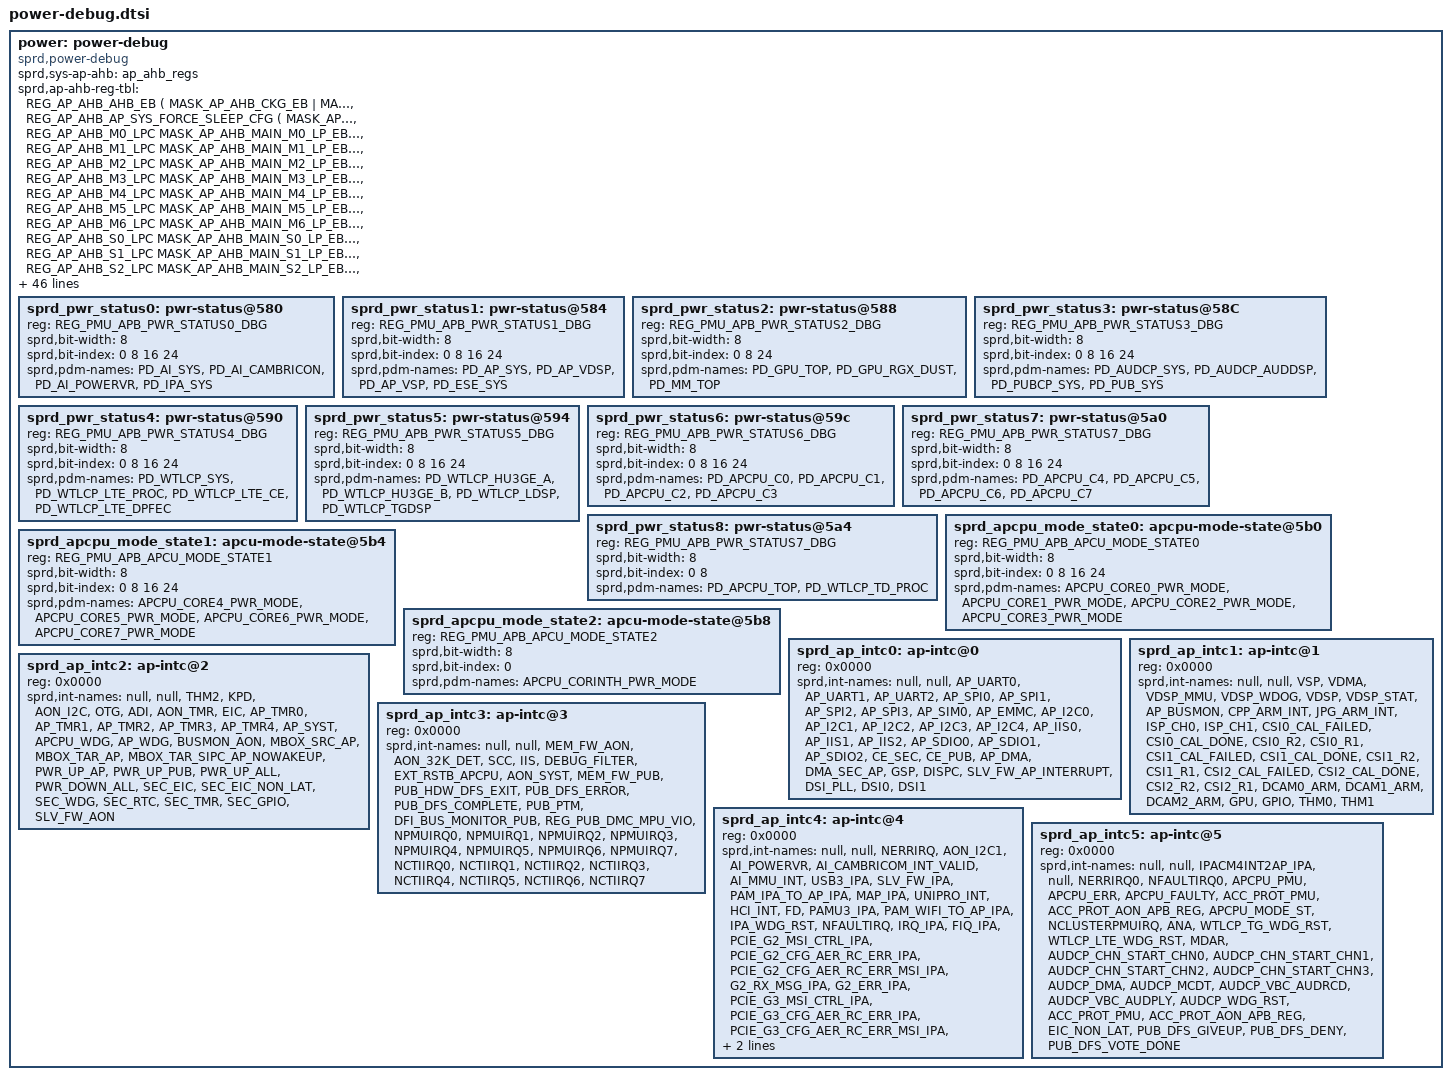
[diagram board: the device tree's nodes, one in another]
/*
 * Spreadtrum Roc1 SoC DTS file
 *
 * Copyright (C) 2018, Spreadtrum Communications Inc.
 *
 * This file is licensed under a dual GPLv2 or X11 license.
 */

	power: power-debug {
		compatible = "sprd,power-debug";
		#address-cells = <1>;
		#size-cells = <0>;

		sprd,sys-ap-ahb = <&ap_ahb_regs>;

		/* <reg-addr mask expect-value> */
		sprd,ap-ahb-reg-tbl =
			<REG_AP_AHB_AHB_EB
			( MASK_AP_AHB_CKG_EB
			| MASK_AP_AHB_DMA_EB
			| MASK_AP_AHB_DMA_ENABLE
			| MASK_AP_AHB_VSP_EB
			| MASK_AP_AHB_DISPC_EB
			| MASK_AP_AHB_DSI_EB )
			MASK_AP_AHB_CKG_EB>,
			<REG_AP_AHB_AP_SYS_FORCE_SLEEP_CFG
			( MASK_AP_AHB_AXI_LP_CTRL_DISABLE
			| MASK_AP_AHB_PERI_FORCE_OFF )
			( MASK_AP_AHB_AXI_LP_CTRL_DISABLE
			| MASK_AP_AHB_PERI_FORCE_OFF)>,
			<REG_AP_AHB_M0_LPC MASK_AP_AHB_MAIN_M0_LP_EB MASK_AP_AHB_MAIN_M0_LP_EB>,
			<REG_AP_AHB_M1_LPC MASK_AP_AHB_MAIN_M1_LP_EB MASK_AP_AHB_MAIN_M1_LP_EB>,
			<REG_AP_AHB_M2_LPC MASK_AP_AHB_MAIN_M2_LP_EB MASK_AP_AHB_MAIN_M2_LP_EB>,
			<REG_AP_AHB_M3_LPC MASK_AP_AHB_MAIN_M3_LP_EB MASK_AP_AHB_MAIN_M3_LP_EB>,
			<REG_AP_AHB_M4_LPC MASK_AP_AHB_MAIN_M4_LP_EB MASK_AP_AHB_MAIN_M4_LP_EB>,
			<REG_AP_AHB_M5_LPC MASK_AP_AHB_MAIN_M5_LP_EB MASK_AP_AHB_MAIN_M5_LP_EB>,
			<REG_AP_AHB_M6_LPC MASK_AP_AHB_MAIN_M6_LP_EB MASK_AP_AHB_MAIN_M6_LP_EB>,
			<REG_AP_AHB_S0_LPC MASK_AP_AHB_MAIN_S0_LP_EB MASK_AP_AHB_MAIN_S0_LP_EB>,
			<REG_AP_AHB_S1_LPC MASK_AP_AHB_MAIN_S1_LP_EB MASK_AP_AHB_MAIN_S1_LP_EB>,
			<REG_AP_AHB_S2_LPC MASK_AP_AHB_MAIN_S2_LP_EB MASK_AP_AHB_MAIN_S2_LP_EB>,
			<REG_AP_AHB_S3_LPC MASK_AP_AHB_MAIN_S3_LP_EB MASK_AP_AHB_MAIN_S3_LP_EB>,
			<REG_AP_AHB_S4_LPC MASK_AP_AHB_MAIN_S4_LP_EB MASK_AP_AHB_MAIN_S4_LP_EB>,
			<REG_AP_AHB_S5_LPC MASK_AP_AHB_MAIN_S5_LP_EB MASK_AP_AHB_MAIN_S5_LP_EB>,
			<REG_AP_AHB_S6_LPC MASK_AP_AHB_MAIN_S6_LP_EB MASK_AP_AHB_MAIN_S6_LP_EB>,
			<REG_AP_AHB_MERGE_M1_LPC MASK_AP_AHB_MERGE_M1_LP_EB MASK_AP_AHB_MERGE_M1_LP_EB>,
			<REG_AP_AHB_MERGE_S0_LPC MASK_AP_AHB_MERGE_S0_LP_EB MASK_AP_AHB_MERGE_S0_LP_EB>,
			<REG_AP_AHB_DISP_ASYNC_BRG MASK_AP_AHB_DISP_ASYNC_BRG_LP_EB MASK_AP_AHB_DISP_ASYNC_BRG_LP_EB>,
			<REG_AP_AHB_AP_ASYNC_BRG MASK_AP_AHB_AP_ASYNC_BRG_LP_EB MASK_AP_AHB_AP_ASYNC_BRG_LP_EB>;

		sprd,sys-ap-apb = <&ap_apb_regs>;

		sprd,ap-apb-reg-tbl =
			<REG_AP_APB_APB_EB
			( MASK_AP_APB_CE_PUB_EB
			| MASK_AP_APB_CE_SEC_EB
			| MASK_AP_APB_EMMC_EB
			| MASK_AP_APB_SDIO2_EB
			| MASK_AP_APB_SDIO1_EB
			| MASK_AP_APB_SDIO0_EB
			| MASK_AP_APB_UART2_EB
			| MASK_AP_APB_UART1_EB
			| MASK_AP_APB_UART0_EB
			| MASK_AP_APB_I2C4_EB
			| MASK_AP_APB_I2C3_EB
			| MASK_AP_APB_I2C2_EB
			| MASK_AP_APB_I2C1_EB
			| MASK_AP_APB_I2C0_EB
			| MASK_AP_APB_SPI3_EB
			| MASK_AP_APB_SPI2_EB
			| MASK_AP_APB_SPI1_EB
			| MASK_AP_APB_SPI0_EB
			| MASK_AP_APB_IIS2_EB
			| MASK_AP_APB_IIS1_EB
			| MASK_AP_APB_IIS0_EB
			| MASK_AP_APB_SIM0_EB )
			0x00000000>,
			<REG_AP_APB_EB_SEC
			( MASK_AP_APB_SPI3_EB_SEC
			| MASK_AP_APB_SPI2_EB_SEC
			| MASK_AP_APB_SPI1_EB_SEC
			| MASK_AP_APB_SPI0_EB_SEC
			| MASK_AP_APB_I2C4_EB_SEC
			| MASK_AP_APB_I2C3_EB_SEC
			| MASK_AP_APB_I2C2_EB_SEC
			| MASK_AP_APB_I2C1_EB_SEC
			| MASK_AP_APB_I2C0_EB_SEC )
			0x00000000>,
			<REG_AP_APB_APB_EB1
			( MASK_AP_APB_UFS_UTP_EB
			| MASK_AP_APB_UFS_HCI_EB
			| MASK_AP_APB_UFS_UNIPRO_EB
			| MASK_AP_APB_UFS_EB )
			0x00000000>;

		sprd,sys-pmu-apb = <&pmu_apb_regs>;

		sprd,pmu-apb-reg-tbl =
			<REG_PMU_APB_PUB_SYS_AUTO_LIGHT_SLEEP_ENABLE MASK_PMU_APB_PUB_SYS_AUTO_LIGHT_SLEEP_ENABLE 0x00000000>,
			<REG_PMU_APB_SLEEP_CTRL
			( MASK_PMU_APB_IPA_DEEP_SLEEP
			| MASK_PMU_APB_SP_SYS_DEEP_SLEEP
			| MASK_PMU_APB_AUDCP_DEEP_SLEEP
			| MASK_PMU_APB_PUB_SYS_DEEP_SLEEP
			| MASK_PMU_APB_ESE_DEEP_SLEEP
			| MASK_PMU_APB_PUBCP_DEEP_SLEEP
			| MASK_PMU_APB_WTLCP_DEEP_SLEEP
			| MASK_PMU_APB_AP_DEEP_SLEEP )
			0x00000000>,
			<REG_PMU_APB_SLEEP_STATUS
			( MASK_PMU_APB_IPA_SLP_STATUS
			| MASK_PMU_APB_SP_SYS_SLP_STATUS
			| MASK_PMU_APB_ESE_SLP_STATUS
			| MASK_PMU_APB_AUDCP_SLP_STATUS
			| MASK_PMU_APB_PUBCP_SLP_STATUS
			| MASK_PMU_APB_WTLCP_SLP_STATUS
			| MASK_PMU_APB_AP_SLP_STATUS )
			0x00000000>,
			<REG_PMU_APB_LIGHT_SLEEP_ENABLE
			( MASK_PMU_APB_APCPU_TOP_SMART_LSLP_ENA
			| MASK_PMU_APB_AI_SMART_LSLP_ENA
			| MASK_PMU_APB_MM_SMART_LSLP_ENA
			| MASK_PMU_APB_GPU_SMART_LSLP_ENA
			| MASK_PMU_APB_IPA_SMART_LSLP_ENA
			| MASK_PMU_APB_ESE_SMART_LSLP_ENA
			| MASK_PMU_APB_AUDCP_SYS_SMART_LSLP_ENA
			| MASK_PMU_APB_AON_SMART_LSLP_ENA
			| MASK_PMU_APB_WTLCP_SMART_LSLP_ENA
			| MASK_PMU_APB_PUBCP_SMART_LSLP_ENA
			| MASK_PMU_APB_AP_SMART_LSLP_ENA
			| MASK_PMU_APB_PUB_SYS_SMART_LSLP_ENA
			| MASK_PMU_APB_MM_LSLP_ENA
			| MASK_PMU_APB_GPU_LSLP_ENA
			| MASK_PMU_APB_IPA_LSLP_ENA
			| MASK_PMU_APB_ESE_LSLP_ENA
			| MASK_PMU_APB_AUDCP_SYS_LSLP_ENA
			| MASK_PMU_APB_AON_LSLP_ENA
			| MASK_PMU_APB_WTLCP_LSLP_ENA
			| MASK_PMU_APB_PUBCP_LSLP_ENA
			| MASK_PMU_APB_AP_LSLP_ENA )
			0x00000000>,
			<REG_PMU_APB_AXI_LP_CTRL_DISABLE MASK_PMU_APB_AXI_LP_CTRL_DISABLE MASK_PMU_APB_AXI_LP_CTRL_DISABLE>;

		sprd,sys-aon-apb = <&aon_apb_regs>;

		sprd,aon-apb-reg-tbl =
			<REG_AON_APB_APB_EB0
			( MASK_AON_APB_PROBE_EB
			| MASK_AON_APB_AUX1_EB )
			0x00000000>,
			<REG_AON_APB_APCPU_DEBUG_PWR_LP_CTRL MASK_AON_APB_APCPU_LP_EB_DEBUG_PWR 0x00000000>,
			<REG_AON_APB_APCPU_CLUSTER_ATB_LPC_CTRL MASK_AON_APB_APCPU_CLUSTER_ATB_LP_EB 0x00000000>,
			<REG_AON_APB_APCPU_CLUSTER_APB_LPC_CTRL MASK_AON_APB_APCPU_CLUSTER_APB_LP_EB 0x00000000>,
			<REG_AON_APB_APCPU_CLUSTER_GIC_LPC_CTRL MASK_AON_APB_APCPU_CLUSTER_GIC_LP_EB 0x00000000>,
			<REG_AON_APB_APCPU_GIC600_GIC_LPC_CTRL MASK_AON_APB_APCPU_GIC600_GIC_LP_EB 0x00000000>,
			<REG_AON_APB_APCPU_DBG_BLK_LPC_CTRL MASK_AON_APB_APCPU_DBG_BLK_LP_EB 0x00000000>,
			<REG_AON_APB_APCPU_TOP_MTX_M0_LPC_CTRL
			( MASK_AON_APB_APCPU_TOP_MTX_MIAN_LP_EB
			| MASK_AON_APB_APCPU_TOP_MTX_S3_LP_EB
			| MASK_AON_APB_APCPU_TOP_MTX_S1_LP_EB
			| MASK_AON_APB_APCPU_TOP_MTX_S0_LP_EB
			| MASK_AON_APB_APCPU_TOP_MTX_M3_LP_EB
			| MASK_AON_APB_APCPU_TOP_MTX_M2_LP_EB
			| MASK_AON_APB_APCPU_TOP_MTX_M0_LP_EB )
			0x00000000>,
			<REG_AON_APB_APCPU_CLUSTER_SCU_LPC_CTRL MASK_AON_APB_APCPU_CLUSTER_SCU_LP_EB 0x00000000>,
			<REG_AON_APB_APCPU_DDR_AB_LPC_CTRL
			( MASK_AON_APB_APCPU_DDR_AB0_LP_EB
			| MASK_AON_APB_APCPU_DDR_AB1_LP_EB )
			0x00000000>;

		sprd,sys-ap-intc = <&ap_intc0_regs &ap_intc1_regs
				&ap_intc2_regs &ap_intc3_regs
				&ap_intc4_regs &ap_intc5_regs>;

		sprd,ap-intc = <&sprd_ap_intc0 &sprd_ap_intc1 &sprd_ap_intc2
				&sprd_ap_intc3 &sprd_ap_intc4 &sprd_ap_intc5>;

		sprd,pdm-name = <&sprd_pwr_status0 &sprd_pwr_status1
				&sprd_pwr_status2 &sprd_pwr_status3
				&sprd_pwr_status4 &sprd_pwr_status5
				&sprd_pwr_status6 &sprd_pwr_status7
				&sprd_pwr_status8 &sprd_apcpu_mode_state0
				&sprd_apcpu_mode_state1 &sprd_apcpu_mode_state2>;

		sprd_pwr_status0: pwr-status@580 {
			reg = <REG_PMU_APB_PWR_STATUS0_DBG>;
			sprd,bit-width = <8>;
			sprd,bit-index = <0 8 16 24>;
			sprd,pdm-names = "PD_AI_SYS", "PD_AI_CAMBRICON",
				"PD_AI_POWERVR", "PD_IPA_SYS";
		};
		sprd_pwr_status1: pwr-status@584 {
			reg = <REG_PMU_APB_PWR_STATUS1_DBG>;
			sprd,bit-width = <8>;
			sprd,bit-index = <0 8 16 24>;
			sprd,pdm-names = "PD_AP_SYS", "PD_AP_VDSP",
				"PD_AP_VSP", "PD_ESE_SYS";
		};
		sprd_pwr_status2: pwr-status@588 {
			reg = <REG_PMU_APB_PWR_STATUS2_DBG>;
			sprd,bit-width = <8>;
			sprd,bit-index = <0 8 24>;
			sprd,pdm-names = "PD_GPU_TOP", "PD_GPU_RGX_DUST",
				"PD_MM_TOP";
		};
		sprd_pwr_status3: pwr-status@58C {
			reg = <REG_PMU_APB_PWR_STATUS3_DBG>;
			sprd,bit-width = <8>;
			sprd,bit-index = <0 8 16 24>;
			sprd,pdm-names = "PD_AUDCP_SYS", "PD_AUDCP_AUDDSP",
				"PD_PUBCP_SYS", "PD_PUB_SYS";
		};
		sprd_pwr_status4: pwr-status@590 {
			reg = <REG_PMU_APB_PWR_STATUS4_DBG>;
			sprd,bit-width = <8>;
			sprd,bit-index = <0 8 16 24>;
			sprd,pdm-names = "PD_WTLCP_SYS", "PD_WTLCP_LTE_PROC",
				"PD_WTLCP_LTE_CE", "PD_WTLCP_LTE_DPFEC";
		};
		sprd_pwr_status5: pwr-status@594 {
			reg = <REG_PMU_APB_PWR_STATUS5_DBG>;
			sprd,bit-width = <8>;
			sprd,bit-index = <0 8 16 24>;
			sprd,pdm-names = "PD_WTLCP_HU3GE_A", "PD_WTLCP_HU3GE_B",
				"PD_WTLCP_LDSP", "PD_WTLCP_TGDSP";
		};
		sprd_pwr_status6: pwr-status@59c{
			reg = <REG_PMU_APB_PWR_STATUS6_DBG>;
			sprd,bit-width = <8>;
			sprd,bit-index = <0 8 16 24>;
			sprd,pdm-names = "PD_APCPU_C0", "PD_APCPU_C1",
				"PD_APCPU_C2", "PD_APCPU_C3";
		};
		sprd_pwr_status7: pwr-status@5a0 {
			reg = <REG_PMU_APB_PWR_STATUS7_DBG>;
			sprd,bit-width = <8>;
			sprd,bit-index = <0 8 16 24>;
			sprd,pdm-names = "PD_APCPU_C4", "PD_APCPU_C5",
				"PD_APCPU_C6", "PD_APCPU_C7";
		};
		sprd_pwr_status8: pwr-status@5a4 {
			reg = <REG_PMU_APB_PWR_STATUS7_DBG>;
			sprd,bit-width = <8>;
			sprd,bit-index = <0 8>;
			sprd,pdm-names = "PD_APCPU_TOP", "PD_WTLCP_TD_PROC";
		};
		sprd_apcpu_mode_state0: apcpu-mode-state@5b0 {
			reg = <REG_PMU_APB_APCU_MODE_STATE0>;
			sprd,bit-width = <8>;
			sprd,bit-index = <0 8 16 24>;
			sprd,pdm-names = "APCPU_CORE0_PWR_MODE", "APCPU_CORE1_PWR_MODE",
				"APCPU_CORE2_PWR_MODE", "APCPU_CORE3_PWR_MODE";
		};
		sprd_apcpu_mode_state1: apcu-mode-state@5b4 {
			reg = <REG_PMU_APB_APCU_MODE_STATE1>;
			sprd,bit-width = <8>;
			sprd,bit-index = <0 8 16 24>;
			sprd,pdm-names = "APCPU_CORE4_PWR_MODE", "APCPU_CORE5_PWR_MODE",
				"APCPU_CORE6_PWR_MODE", "APCPU_CORE7_PWR_MODE";
		};
		sprd_apcpu_mode_state2: apcu-mode-state@5b8 {
			reg = <REG_PMU_APB_APCU_MODE_STATE2>;
			sprd,bit-width = <8>;
			sprd,bit-index = <0>;
			sprd,pdm-names = "APCPU_CORINTH_PWR_MODE";
		};

		sprd_ap_intc0: ap-intc@0 {
			reg = <0x0000>;
			sprd,int-names = "null", "null", "AP_UART0", "AP_UART1",
				"AP_UART2", "AP_SPI0",	"AP_SPI1", "AP_SPI2",
				"AP_SPI3", "AP_SIM0", "AP_EMMC",	"AP_I2C0",
				"AP_I2C1", "AP_I2C2", "AP_I2C3", "AP_I2C4",
				"AP_IIS0", "AP_IIS1", "AP_IIS2", "AP_SDIO0",
				"AP_SDIO1", "AP_SDIO2", "CE_SEC", "CE_PUB",
				"AP_DMA", "DMA_SEC_AP", "GSP", "DISPC",
				"SLV_FW_AP_INTERRUPT", "DSI_PLL", "DSI0",
				"DSI1";
		};
		sprd_ap_intc1: ap-intc@1 {
			reg = <0x0000>;
			sprd,int-names = "null", "null", "VSP", "VDMA",
				"VDSP_MMU", "VDSP_WDOG", "VDSP", "VDSP_STAT",
				"AP_BUSMON", "CPP_ARM_INT",
				"JPG_ARM_INT", "ISP_CH0", "ISP_CH1",
				"CSI0_CAL_FAILED", "CSI0_CAL_DONE",
				"CSI0_R2", "CSI0_R1", "CSI1_CAL_FAILED",
				"CSI1_CAL_DONE", "CSI1_R2", "CSI1_R1",
				"CSI2_CAL_FAILED", "CSI2_CAL_DONE",
				"CSI2_R2", "CSI2_R1", "DCAM0_ARM",
				"DCAM1_ARM", "DCAM2_ARM", "GPU", "GPIO",
				"THM0", "THM1";
		};
		sprd_ap_intc2: ap-intc@2 {
			reg = <0x0000>;
			sprd,int-names = "null", "null", "THM2", "KPD",
				"AON_I2C", "OTG", "ADI", "AON_TMR",
				"EIC", "AP_TMR0", "AP_TMR1", "AP_TMR2",
				"AP_TMR3", "AP_TMR4", "AP_SYST", "APCPU_WDG",
				"AP_WDG", "BUSMON_AON", "MBOX_SRC_AP",
				"MBOX_TAR_AP", "MBOX_TAR_SIPC_AP_NOWAKEUP",
				"PWR_UP_AP", "PWR_UP_PUB", "PWR_UP_ALL",
				"PWR_DOWN_ALL", "SEC_EIC", "SEC_EIC_NON_LAT",
				"SEC_WDG", "SEC_RTC", "SEC_TMR", "SEC_GPIO",
				"SLV_FW_AON";
		};
		sprd_ap_intc3: ap-intc@3 {
			reg = <0x0000>;
			sprd,int-names = "null", "null", "MEM_FW_AON", "AON_32K_DET",
				"SCC", "IIS", "DEBUG_FILTER", "EXT_RSTB_APCPU",
				"AON_SYST", "MEM_FW_PUB", "PUB_HDW_DFS_EXIT",
				"PUB_DFS_ERROR", "PUB_DFS_COMPLETE", "PUB_PTM",
				"DFI_BUS_MONITOR_PUB", "REG_PUB_DMC_MPU_VIO",
				"NPMUIRQ0", "NPMUIRQ1", "NPMUIRQ2", "NPMUIRQ3",
				"NPMUIRQ4", "NPMUIRQ5", "NPMUIRQ6", "NPMUIRQ7",
				"NCTIIRQ0", "NCTIIRQ1", "NCTIIRQ2", "NCTIIRQ3",
				"NCTIIRQ4", "NCTIIRQ5", "NCTIIRQ6", "NCTIIRQ7";
		};
		sprd_ap_intc4: ap-intc@4 {
			reg = <0x0000>;
			sprd,int-names = "null", "null", "NERRIRQ",
				"AON_I2C1", "AI_POWERVR",
				"AI_CAMBRICOM_INT_VALID", "AI_MMU_INT", "USB3_IPA",
				"SLV_FW_IPA", "PAM_IPA_TO_AP_IPA", "MAP_IPA",
				"UNIPRO_INT", "HCI_INT", "FD", "PAMU3_IPA",
				"PAM_WIFI_TO_AP_IPA", "IPA_WDG_RST", "NFAULTIRQ",
				"IRQ_IPA", "FIQ_IPA", "PCIE_G2_MSI_CTRL_IPA",
				"PCIE_G2_CFG_AER_RC_ERR_IPA", "PCIE_G2_CFG_AER_RC_ERR_MSI_IPA",
				"G2_RX_MSG_IPA", "G2_ERR_IPA", "PCIE_G3_MSI_CTRL_IPA",
				"PCIE_G3_CFG_AER_RC_ERR_IPA", "PCIE_G3_CFG_AER_RC_ERR_MSI_IPA",
				"G3_RX_MSG_IPA", "G3_ERR_IPA", "SLV_FW_1_IPA",
				"PAMU3_COMFIFO_IPA";
		};
		sprd_ap_intc5: ap-intc@5 {
			reg = <0x0000>;
			sprd,int-names = "null", "null", "IPACM4INT2AP_IPA", "null",
				"NERRIRQ0", "NFAULTIRQ0", "APCPU_PMU",
				"APCPU_ERR", "APCPU_FAULTY", "ACC_PROT_PMU",
				"ACC_PROT_AON_APB_REG",	"APCPU_MODE_ST", "NCLUSTERPMUIRQ",
				"ANA", "WTLCP_TG_WDG_RST", "WTLCP_LTE_WDG_RST",
				"MDAR", "AUDCP_CHN_START_CHN0",
				"AUDCP_CHN_START_CHN1", "AUDCP_CHN_START_CHN2",
				"AUDCP_CHN_START_CHN3", "AUDCP_DMA",
				"AUDCP_MCDT", "AUDCP_VBC_AUDRCD",
				"AUDCP_VBC_AUDPLY", "AUDCP_WDG_RST",
				"ACC_PROT_PMU", "ACC_PROT_AON_APB_REG",
				"EIC_NON_LAT", "PUB_DFS_GIVEUP",
				"PUB_DFS_DENY", "PUB_DFS_VOTE_DONE";
		};
	};
